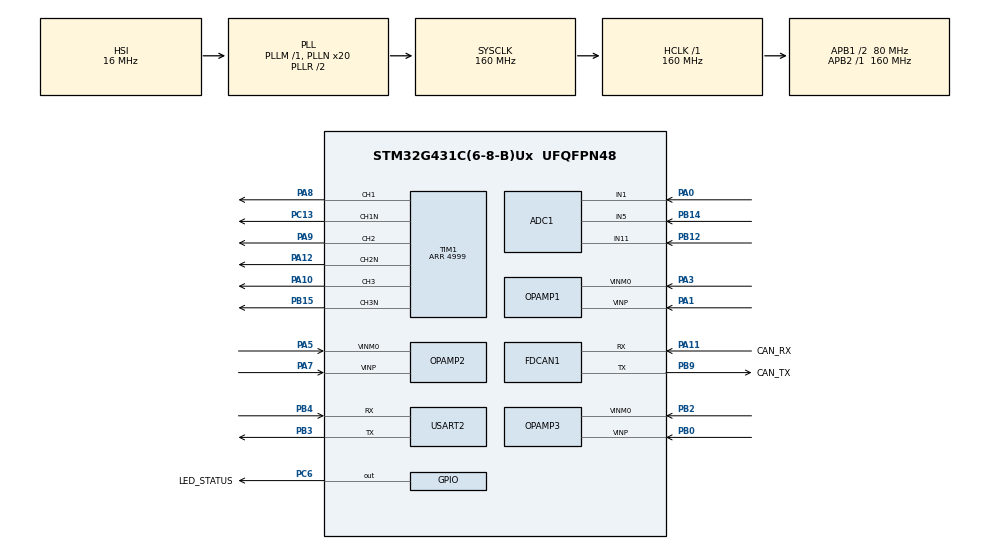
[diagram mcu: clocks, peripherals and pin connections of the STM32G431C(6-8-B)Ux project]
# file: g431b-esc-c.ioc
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ADC1.Channel-0\#ChannelRegularConversion=ADC_CHANNEL_VOPAMP1
ADC1.Channel-1\#ChannelRegularConversion=ADC_CHANNEL_VOPAMP1
ADC1.Channel-2\#ChannelRegularConversion=ADC_CHANNEL_11
ADC1.Channel-3\#ChannelRegularConversion=ADC_CHANNEL_1
ADC1.Channel-4\#ChannelRegularConversion=ADC_CHANNEL_5
ADC1.EOCSelection=ADC_EOC_SEQ_CONV
ADC1.ExternalTrigConv=ADC_EXTERNALTRIG_T1_TRGO
ADC1.NbrOfConversion=5
ADC1.NbrOfConversionFlag=1
ADC1.OffsetNumber-0\#ChannelRegularConversion=ADC_OFFSET_NONE
ADC1.OffsetNumber-1\#ChannelRegularConversion=ADC_OFFSET_NONE
ADC1.OffsetNumber-2\#ChannelRegularConversion=ADC_OFFSET_NONE
ADC1.OffsetNumber-3\#ChannelRegularConversion=ADC_OFFSET_NONE
ADC1.OffsetNumber-4\#ChannelRegularConversion=ADC_OFFSET_NONE
ADC1.Overrun=ADC_OVR_DATA_OVERWRITTEN
ADC1.Rank-0\#ChannelRegularConversion=1
ADC1.Rank-1\#ChannelRegularConversion=2
ADC1.Rank-2\#ChannelRegularConversion=3
ADC1.Rank-3\#ChannelRegularConversion=4
ADC1.Rank-4\#ChannelRegularConversion=5
ADC1.SamplingTime-0\#ChannelRegularConversion=ADC_SAMPLETIME_2CYCLES_5
ADC1.SamplingTime-1\#ChannelRegularConversion=ADC_SAMPLETIME_2CYCLES_5
ADC1.SamplingTime-2\#ChannelRegularConversion=ADC_SAMPLETIME_2CYCLES_5
ADC1.SamplingTime-3\#ChannelRegularConversion=ADC_SAMPLETIME_2CYCLES_5
ADC1.SamplingTime-4\#ChannelRegularConversion=ADC_SAMPLETIME_2CYCLES_5
ADC1.master=1
ADC2.Channel-0\#ChannelRegularConversion=ADC_CHANNEL_VOPAMP2
ADC2.Channel-1\#ChannelRegularConversion=ADC_CHANNEL_VOPAMP2
ADC2.Channel-2\#ChannelRegularConversion=ADC_CHANNEL_VOPAMP3_ADC2
ADC2.EOCSelection=ADC_EOC_SEQ_CONV
ADC2.ExternalTrigConv=ADC_EXTERNALTRIG_T1_TRGO
ADC2.NbrOfConversion=3
ADC2.NbrOfConversionFlag=1
ADC2.OffsetNumber-0\#ChannelRegularConversion=ADC_OFFSET_NONE
ADC2.OffsetNumber-1\#ChannelRegularConversion=ADC_OFFSET_NONE
ADC2.OffsetNumber-2\#ChannelRegularConversion=ADC_OFFSET_NONE
ADC2.Overrun=ADC_OVR_DATA_OVERWRITTEN
ADC2.Rank-0\#ChannelRegularConversion=1
ADC2.Rank-1\#ChannelRegularConversion=2
ADC2.Rank-2\#ChannelRegularConversion=3
ADC2.SamplingTime-0\#ChannelRegularConversion=ADC_SAMPLETIME_2CYCLES_5
ADC2.SamplingTime-1\#ChannelRegularConversion=ADC_SAMPLETIME_2CYCLES_5
ADC2.SamplingTime-2\#ChannelRegularConversion=ADC_SAMPLETIME_2CYCLES_5
Dma.ADC1.2.Direction=DMA_PERIPH_TO_MEMORY
Dma.ADC1.2.EventEnable=DISABLE
Dma.ADC1.2.Instance=DMA1_Channel3
Dma.ADC1.2.MemDataAlignment=DMA_MDATAALIGN_HALFWORD
Dma.ADC1.2.MemInc=DMA_MINC_ENABLE
Dma.ADC1.2.Mode=DMA_CIRCULAR
Dma.ADC1.2.PeriphDataAlignment=DMA_PDATAALIGN_HALFWORD
Dma.ADC1.2.PeriphInc=DMA_PINC_DISABLE
Dma.ADC1.2.Polarity=HAL_DMAMUX_REQ_GEN_RISING
Dma.ADC1.2.Priority=DMA_PRIORITY_LOW
Dma.ADC1.2.RequestNumber=1
Dma.ADC1.2.SignalID=NONE
Dma.ADC1.2.SyncEnable=DISABLE
Dma.ADC1.2.SyncPolarity=HAL_DMAMUX_SYNC_NO_EVENT
Dma.ADC1.2.SyncRequestNumber=1
Dma.ADC1.2.SyncSignalID=NONE
Dma.ADC2.3.Direction=DMA_PERIPH_TO_MEMORY
Dma.ADC2.3.EventEnable=DISABLE
Dma.ADC2.3.Instance=DMA1_Channel4
Dma.ADC2.3.MemDataAlignment=DMA_MDATAALIGN_HALFWORD
Dma.ADC2.3.MemInc=DMA_MINC_ENABLE
Dma.ADC2.3.Mode=DMA_CIRCULAR
Dma.ADC2.3.PeriphDataAlignment=DMA_PDATAALIGN_HALFWORD
Dma.ADC2.3.PeriphInc=DMA_PINC_DISABLE
Dma.ADC2.3.Polarity=HAL_DMAMUX_REQ_GEN_RISING
Dma.ADC2.3.Priority=DMA_PRIORITY_LOW
Dma.ADC2.3.RequestNumber=1
Dma.ADC2.3.SignalID=NONE
Dma.ADC2.3.SyncEnable=DISABLE
Dma.ADC2.3.SyncPolarity=HAL_DMAMUX_SYNC_NO_EVENT
Dma.ADC2.3.SyncRequestNumber=1
Dma.ADC2.3.SyncSignalID=NONE
Dma.Request0=USART2_RX
Dma.Request1=USART2_TX
Dma.Request2=ADC1
Dma.Request3=ADC2
Dma.USART2_RX.0.Direction=DMA_PERIPH_TO_MEMORY
Dma.USART2_RX.0.EventEnable=DISABLE
Dma.USART2_RX.0.Instance=DMA1_Channel1
Dma.USART2_RX.0.MemDataAlignment=DMA_MDATAALIGN_BYTE
Dma.USART2_RX.0.MemInc=DMA_MINC_ENABLE
Dma.USART2_RX.0.Mode=DMA_CIRCULAR
Dma.USART2_RX.0.PeriphDataAlignment=DMA_PDATAALIGN_BYTE
Dma.USART2_RX.0.PeriphInc=DMA_PINC_DISABLE
Dma.USART2_RX.0.Polarity=HAL_DMAMUX_REQ_GEN_RISING
Dma.USART2_RX.0.Priority=DMA_PRIORITY_LOW
Dma.USART2_RX.0.RequestNumber=1
Dma.USART2_RX.0.SignalID=NONE
Dma.USART2_RX.0.SyncEnable=DISABLE
Dma.USART2_RX.0.SyncPolarity=HAL_DMAMUX_SYNC_NO_EVENT
Dma.USART2_RX.0.SyncRequestNumber=1
Dma.USART2_RX.0.SyncSignalID=NONE
Dma.USART2_TX.1.Direction=DMA_MEMORY_TO_PERIPH
Dma.USART2_TX.1.EventEnable=DISABLE
Dma.USART2_TX.1.Instance=DMA1_Channel2
Dma.USART2_TX.1.MemDataAlignment=DMA_MDATAALIGN_BYTE
Dma.USART2_TX.1.MemInc=DMA_MINC_ENABLE
Dma.USART2_TX.1.Mode=DMA_NORMAL
Dma.USART2_TX.1.PeriphDataAlignment=DMA_PDATAALIGN_BYTE
Dma.USART2_TX.1.PeriphInc=DMA_PINC_DISABLE
Dma.USART2_TX.1.Polarity=HAL_DMAMUX_REQ_GEN_RISING
Dma.USART2_TX.1.Priority=DMA_PRIORITY_LOW
Dma.USART2_TX.1.RequestNumber=1
Dma.USART2_TX.1.SignalID=NONE
Dma.USART2_TX.1.SyncEnable=DISABLE
Dma.USART2_TX.1.SyncPolarity=HAL_DMAMUX_SYNC_NO_EVENT
Dma.USART2_TX.1.SyncRequestNumber=1
Dma.USART2_TX.1.SyncSignalID=NONE
FDCAN1.AutoRetransmission=ENABLE
FDCAN1.CalculateBaudRateNominal=1000000
FDCAN1.CalculateTimeBitNominal=1000
FDCAN1.CalculateTimeQuantumNominal=12.5
FDCAN1.DataSyncJumpWidth=7
FDCAN1.DataTimeSeg1=32
FDCAN1.DataTimeSeg2=7
FDCAN1.FrameFormat=FDCAN_FRAME_FD_BRS
FDCAN1.NominalPrescaler=1
FDCAN1.NominalSyncJumpWidth=12
FDCAN1.NominalTimeSeg1=67
FDCAN1.NominalTimeSeg2=12
Mcu.Family=STM32G4
Mcu.Name=STM32G431C(6-8-B)Ux
Mcu.Package=UFQFPN48
NVIC.ADC1_2_IRQn=true\:0\:0\:false\:false\:true\:true\:true\:true
NVIC.DMA1_Channel1_IRQn=true\:0\:0\:false\:false\:true\:false\:true\:true
NVIC.DMA1_Channel2_IRQn=true\:0\:0\:false\:false\:true\:false\:true\:true
NVIC.DMA1_Channel3_IRQn=true\:0\:0\:false\:false\:true\:false\:true\:true
NVIC.DMA1_Channel4_IRQn=true\:0\:0\:false\:false\:true\:false\:true\:true
NVIC.FDCAN1_IT0_IRQn=true\:0\:0\:false\:false\:true\:true\:true\:true
NVIC.PriorityGroup=NVIC_PRIORITYGROUP_4
NVIC.TIM3_IRQn=true\:0\:0\:false\:false\:true\:true\:true\:true
NVIC.USART2_IRQn=true\:0\:0\:false\:false\:true\:true\:true\:true
OPAMP1.PgaGain=OPAMP_PGA_GAIN_16_OR_MINUS_15
OPAMP2.PgaGain=OPAMP_PGA_GAIN_16_OR_MINUS_15
OPAMP3.PgaGain=OPAMP_PGA_GAIN_16_OR_MINUS_15
PA0.Mode=IN1-Single-Ended
PA0.Signal=ADC1_IN1
PA1.Mode=PGA Internally connected_IO0_BIAS
PA1.Signal=OPAMP1_VINP
PA10.Signal=S_TIM1_CH3
PA11.GPIO_Label=CAN_RX
PA11.Mode=FDCAN_Activate
PA11.Signal=FDCAN1_RX
PA12.Mode=PWM Generation2 CH2 CH2N
PA12.Signal=TIM1_CH2N
PA13.GPIO_Label=SWDIO
PA13.Mode=Serial_Wire
PA13.Signal=SYS_JTMS-SWDIO
PA14.GPIO_Label=SWCLK
PA14.Mode=Serial_Wire
PA14.Signal=SYS_JTCK-SWCLK
PA3.Mode=PGA Internally connected_IO0_BIAS
PA3.Signal=OPAMP1_VINM0
PA5.Mode=PGA Internally connected_IO0_BIAS
PA5.Signal=OPAMP2_VINM0
PA7.Mode=PGA Internally connected_IO0_BIAS
PA7.Signal=OPAMP2_VINP
PA8.Signal=S_TIM1_CH1
PA9.Signal=S_TIM1_CH2
PB0.Mode=PGA Internally connected_IO0_BIAS
PB0.Signal=OPAMP3_VINP
PB12.Mode=IN11-Single-Ended
PB12.Signal=ADC1_IN11
PB14.Mode=IN5-Single-Ended
PB14.Signal=ADC1_IN5
PB15.Mode=PWM Generation3 CH3 CH3N
PB15.Signal=TIM1_CH3N
PB2.Mode=PGA Internally connected_IO0_BIAS
PB2.Signal=OPAMP3_VINM0
PB3.Mode=Asynchronous
PB3.Signal=USART2_TX
PB4.Mode=Asynchronous
PB4.Signal=USART2_RX
PB9.GPIO_Label=CAN_TX
PB9.Mode=FDCAN_Activate
PB9.Signal=FDCAN1_TX
PC13.Mode=PWM Generation1 CH1 CH1N
PC13.Signal=TIM1_CH1N
PC6.GPIO_Label=LED_STATUS
PC6.Signal=GPIO_Output
PF0-OSC_IN.Mode=HSE-External-Oscillator
PF0-OSC_IN.Signal=RCC_OSC_IN
PF1-OSC_OUT.Mode=HSE-External-Oscillator
PF1-OSC_OUT.Signal=RCC_OSC_OUT
ProjectManager.HeapSize=0x200
ProjectManager.StackSize=0x400
ProjectManager.TargetToolchain=STM32CubeIDE
RCC.ADC12Freq_Value=160000000
RCC.AHBFreq_Value=160000000
RCC.APB1CLKDivider=RCC_HCLK_DIV2
RCC.APB1Freq_Value=80000000
RCC.APB1TimFreq_Value=160000000
RCC.APB2Freq_Value=160000000
RCC.APB2TimFreq_Value=160000000
RCC.CortexFreq_Value=160000000
RCC.EXTERNAL_CLOCK_VALUE=12288000
RCC.HCLKFreq_Value=160000000
RCC.HSE_VALUE=8000000
RCC.HSI48_VALUE=48000000
RCC.HSI_VALUE=16000000
RCC.LSE_VALUE=32768
RCC.PLLN=20
RCC.PLLQ=RCC_PLLQ_DIV4
RCC.SYSCLKFreq_VALUE=160000000
RCC.SYSCLKSource=RCC_SYSCLKSOURCE_PLLCLK
RCC.USBFreq_Value=80000000
RCC.VCOOutputFreq_Value=320000000
SH.S_TIM1_CH1.0=TIM1_CH1,PWM Generation1 CH1 CH1N
SH.S_TIM1_CH2.0=TIM1_CH2,PWM Generation2 CH2 CH2N
SH.S_TIM1_CH3.0=TIM1_CH3,PWM Generation3 CH3 CH3N
TIM1.Channel-PWM\ Generation1\ CH1\ CH1N=TIM_CHANNEL_1
TIM1.Channel-PWM\ Generation2\ CH2\ CH2N=TIM_CHANNEL_2
TIM1.Channel-PWM\ Generation3\ CH3\ CH3N=TIM_CHANNEL_3
TIM1.CounterMode=TIM_COUNTERMODE_CENTERALIGNED1
TIM1.DeadTime=128
TIM1.PeriodNoDither=4999
TIM1.TIM_MasterOutputTrigger=TIM_TRGO_UPDATE
TIM2.PeriodNoDither=4294967295
TIM2.Prescaler=159
TIM3.PeriodNoDither=999
TIM3.Prescaler=159
USART2.RXFIFOThreshold=RXFIFO_THRESHOLD_HALFFULL
USART2.TXFIFOThreshold=TXFIFO_THRESHOLD_EMPTY
USART2.VirtualMode-Asynchronous=VM_ASYNC
VP_ADC1_OPAMP_INTERNAL1.Mode=IN-OPAMP1
VP_ADC2_OPAMP_INTERNAL2.Mode=IN-OPAMP2
VP_ADC2_OPAMP_INTERNAL3.Mode=IN-OPAMP3
VP_SYS_VS_DBSignals.Mode=DisableDeadBatterySignals
VP_TIM1_VS_ClockSourceINT.Mode=Internal
VP_TIM2_VS_ClockSourceINT.Mode=Internal
VP_TIM3_VS_ClockSourceINT.Mode=Internal
board=custom

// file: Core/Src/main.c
/* USER CODE BEGIN Header */
/**
  ******************************************************************************
  * @file           : main.c
  * @brief          : Main program body
  ******************************************************************************
  * @attention
  *
  * Copyright (c) 2025 STMicroelectronics.
  * All rights reserved.
  *
  * This software is licensed under terms that can be found in the LICENSE file
  * in the root directory of this software component.
  * If no LICENSE file comes with this software, it is provided AS-IS.
  *
  ******************************************************************************
  */
/* USER CODE END Header */
#include "main.h"

ADC_HandleTypeDef hadc1;
ADC_HandleTypeDef hadc2;
DMA_HandleTypeDef hdma_adc1;
DMA_HandleTypeDef hdma_adc2;

FDCAN_HandleTypeDef hfdcan1;

OPAMP_HandleTypeDef hopamp1;
OPAMP_HandleTypeDef hopamp2;
OPAMP_HandleTypeDef hopamp3;

TIM_HandleTypeDef htim1;
TIM_HandleTypeDef htim2;
TIM_HandleTypeDef htim3;

UART_HandleTypeDef huart2;
DMA_HandleTypeDef hdma_usart2_rx;
DMA_HandleTypeDef hdma_usart2_tx;

void SystemClock_Config(void);
static void MX_GPIO_Init(void);
static void MX_DMA_Init(void);
static void MX_FDCAN1_Init(void);
static void MX_USART2_UART_Init(void);
static void MX_TIM2_Init(void);
static void MX_TIM1_Init(void);
static void MX_ADC1_Init(void);
static void MX_OPAMP1_Init(void);
static void MX_OPAMP2_Init(void);
static void MX_OPAMP3_Init(void);
static void MX_ADC2_Init(void);
static void MX_TIM3_Init(void);

int main(void)
{

  /* MCU Configuration--------------------------------------------------------*/

  /* Reset of all peripherals, Initializes the Flash interface and the Systick. */
  HAL_Init();

  /* Configure the system clock */
  SystemClock_Config();

  /* Initialize all configured peripherals */
  MX_GPIO_Init();
  MX_DMA_Init();
  MX_FDCAN1_Init();
  MX_USART2_UART_Init();
  MX_TIM2_Init();
  MX_TIM1_Init();
  MX_ADC1_Init();
  MX_OPAMP1_Init();
  MX_OPAMP2_Init();
  MX_OPAMP3_Init();
  MX_ADC2_Init();
  MX_TIM3_Init();
  /* USER CODE BEGIN 2 */

  HAL_TIM_Base_Start(&htim2);
  __HAL_TIM_SET_COUNTER(&htim2, 0U);
  __HAL_DBGMCU_FREEZE_TIM2();

  extern void QPC_start(void);
  QPC_start();
  /* USER CODE END 2 */

  /* Infinite loop */
  while (1)
  {

  }
}

void SystemClock_Config(void)
{
  RCC_OscInitTypeDef RCC_OscInitStruct = {0};
  RCC_ClkInitTypeDef RCC_ClkInitStruct = {0};

  /** Configure the main internal regulator output voltage
  */
  HAL_PWREx_ControlVoltageScaling(PWR_REGULATOR_VOLTAGE_SCALE1_BOOST);

  /** Initializes the RCC Oscillators according to the specified parameters
  * in the RCC_OscInitTypeDef structure.
  */
  RCC_OscInitStruct.OscillatorType = RCC_OSCILLATORTYPE_HSI;
  RCC_OscInitStruct.HSIState = RCC_HSI_ON;
  RCC_OscInitStruct.HSICalibrationValue = RCC_HSICALIBRATION_DEFAULT;
  RCC_OscInitStruct.PLL.PLLState = RCC_PLL_ON;
  RCC_OscInitStruct.PLL.PLLSource = RCC_PLLSOURCE_HSI;
  RCC_OscInitStruct.PLL.PLLM = RCC_PLLM_DIV1;
  RCC_OscInitStruct.PLL.PLLN = 20;
  RCC_OscInitStruct.PLL.PLLP = RCC_PLLP_DIV2;
  RCC_OscInitStruct.PLL.PLLQ = RCC_PLLQ_DIV4;
  RCC_OscInitStruct.PLL.PLLR = RCC_PLLR_DIV2;
  if (HAL_RCC_OscConfig(&RCC_OscInitStruct) != HAL_OK)
  {
    Error_Handler();
  }

  /** Initializes the CPU, AHB and APB buses clocks
  */
  RCC_ClkInitStruct.ClockType = RCC_CLOCKTYPE_HCLK|RCC_CLOCKTYPE_SYSCLK
                              |RCC_CLOCKTYPE_PCLK1|RCC_CLOCKTYPE_PCLK2;
  RCC_ClkInitStruct.SYSCLKSource = RCC_SYSCLKSOURCE_PLLCLK;
  RCC_ClkInitStruct.AHBCLKDivider = RCC_SYSCLK_DIV1;
  RCC_ClkInitStruct.APB1CLKDivider = RCC_HCLK_DIV2;
  RCC_ClkInitStruct.APB2CLKDivider = RCC_HCLK_DIV1;

  if (HAL_RCC_ClockConfig(&RCC_ClkInitStruct, FLASH_LATENCY_4) != HAL_OK)
  {
    Error_Handler();
  }
}

static void MX_ADC1_Init(void)
{

  ADC_MultiModeTypeDef multimode = {0};
  ADC_ChannelConfTypeDef sConfig = {0};

  /** Common config
  */
  hadc1.Instance = ADC1;
  hadc1.Init.ClockPrescaler = ADC_CLOCK_SYNC_PCLK_DIV4;
  hadc1.Init.Resolution = ADC_RESOLUTION_12B;
  hadc1.Init.DataAlign = ADC_DATAALIGN_RIGHT;
  hadc1.Init.GainCompensation = 0;
  hadc1.Init.ScanConvMode = ADC_SCAN_ENABLE;
  hadc1.Init.EOCSelection = ADC_EOC_SEQ_CONV;
  hadc1.Init.LowPowerAutoWait = DISABLE;
  hadc1.Init.ContinuousConvMode = DISABLE;
  hadc1.Init.NbrOfConversion = 5;
  hadc1.Init.DiscontinuousConvMode = DISABLE;
  hadc1.Init.ExternalTrigConv = ADC_EXTERNALTRIG_T1_TRGO;
  hadc1.Init.ExternalTrigConvEdge = ADC_EXTERNALTRIGCONVEDGE_RISING;
  hadc1.Init.DMAContinuousRequests = DISABLE;
  hadc1.Init.Overrun = ADC_OVR_DATA_OVERWRITTEN;
  hadc1.Init.OversamplingMode = DISABLE;
  if (HAL_ADC_Init(&hadc1) != HAL_OK)
  {
    Error_Handler();
  }

  /** Configure the ADC multi-mode
  */
  multimode.Mode = ADC_MODE_INDEPENDENT;
  if (HAL_ADCEx_MultiModeConfigChannel(&hadc1, &multimode) != HAL_OK)
  {
    Error_Handler();
  }

  /** Configure Regular Channel
  */
  sConfig.Channel = ADC_CHANNEL_VOPAMP1;
  sConfig.Rank = ADC_REGULAR_RANK_1;
  sConfig.SamplingTime = ADC_SAMPLETIME_2CYCLES_5;
  sConfig.SingleDiff = ADC_SINGLE_ENDED;
  sConfig.OffsetNumber = ADC_OFFSET_NONE;
  sConfig.Offset = 0;
  if (HAL_ADC_ConfigChannel(&hadc1, &sConfig) != HAL_OK)
  {
    Error_Handler();
  }

  /** Configure Regular Channel
  */
  sConfig.Rank = ADC_REGULAR_RANK_2;
  if (HAL_ADC_ConfigChannel(&hadc1, &sConfig) != HAL_OK)
  {
    Error_Handler();
  }

  /** Configure Regular Channel
  */
  sConfig.Channel = ADC_CHANNEL_11;
  sConfig.Rank = ADC_REGULAR_RANK_3;
  if (HAL_ADC_ConfigChannel(&hadc1, &sConfig) != HAL_OK)
  {
    Error_Handler();
  }

  /** Configure Regular Channel
  */
  sConfig.Channel = ADC_CHANNEL_1;
  sConfig.Rank = ADC_REGULAR_RANK_4;
  if (HAL_ADC_ConfigChannel(&hadc1, &sConfig) != HAL_OK)
  {
    Error_Handler();
  }

  /** Configure Regular Channel
  */
  sConfig.Channel = ADC_CHANNEL_5;
  sConfig.Rank = ADC_REGULAR_RANK_5;
  if (HAL_ADC_ConfigChannel(&hadc1, &sConfig) != HAL_OK)
  {
    Error_Handler();
  }

}

static void MX_ADC2_Init(void)
{

  ADC_ChannelConfTypeDef sConfig = {0};

  /** Common config
  */
  hadc2.Instance = ADC2;
  hadc2.Init.ClockPrescaler = ADC_CLOCK_SYNC_PCLK_DIV4;
  hadc2.Init.Resolution = ADC_RESOLUTION_12B;
  hadc2.Init.DataAlign = ADC_DATAALIGN_RIGHT;
  hadc2.Init.GainCompensation = 0;
  hadc2.Init.ScanConvMode = ADC_SCAN_ENABLE;
  hadc2.Init.EOCSelection = ADC_EOC_SEQ_CONV;
  hadc2.Init.LowPowerAutoWait = DISABLE;
  hadc2.Init.ContinuousConvMode = DISABLE;
  hadc2.Init.NbrOfConversion = 3;
  hadc2.Init.DiscontinuousConvMode = DISABLE;
  hadc2.Init.ExternalTrigConv = ADC_EXTERNALTRIG_T1_TRGO;
  hadc2.Init.ExternalTrigConvEdge = ADC_EXTERNALTRIGCONVEDGE_RISING;
  hadc2.Init.DMAContinuousRequests = DISABLE;
  hadc2.Init.Overrun = ADC_OVR_DATA_OVERWRITTEN;
  hadc2.Init.OversamplingMode = DISABLE;
  if (HAL_ADC_Init(&hadc2) != HAL_OK)
  {
    Error_Handler();
  }

  /** Configure Regular Channel
  */
  sConfig.Channel = ADC_CHANNEL_VOPAMP2;
  sConfig.Rank = ADC_REGULAR_RANK_1;
  sConfig.SamplingTime = ADC_SAMPLETIME_2CYCLES_5;
  sConfig.SingleDiff = ADC_SINGLE_ENDED;
  sConfig.OffsetNumber = ADC_OFFSET_NONE;
  sConfig.Offset = 0;
  if (HAL_ADC_ConfigChannel(&hadc2, &sConfig) != HAL_OK)
  {
    Error_Handler();
  }

  /** Configure Regular Channel
  */
  sConfig.Rank = ADC_REGULAR_RANK_2;
  if (HAL_ADC_ConfigChannel(&hadc2, &sConfig) != HAL_OK)
  {
    Error_Handler();
  }

  /** Configure Regular Channel
  */
  sConfig.Channel = ADC_CHANNEL_VOPAMP3_ADC2;
  sConfig.Rank = ADC_REGULAR_RANK_3;
  if (HAL_ADC_ConfigChannel(&hadc2, &sConfig) != HAL_OK)
  {
    Error_Handler();
  }

}

static void MX_FDCAN1_Init(void)
{

  hfdcan1.Instance = FDCAN1;
  hfdcan1.Init.ClockDivider = FDCAN_CLOCK_DIV1;
  hfdcan1.Init.FrameFormat = FDCAN_FRAME_FD_BRS;
  hfdcan1.Init.Mode = FDCAN_MODE_NORMAL;
  hfdcan1.Init.AutoRetransmission = ENABLE;
  hfdcan1.Init.TransmitPause = DISABLE;
  hfdcan1.Init.ProtocolException = DISABLE;
  hfdcan1.Init.NominalPrescaler = 1;
  hfdcan1.Init.NominalSyncJumpWidth = 12;
  hfdcan1.Init.NominalTimeSeg1 = 67;
  hfdcan1.Init.NominalTimeSeg2 = 12;
  hfdcan1.Init.DataPrescaler = 1;
  hfdcan1.Init.DataSyncJumpWidth = 7;
  hfdcan1.Init.DataTimeSeg1 = 32;
  hfdcan1.Init.DataTimeSeg2 = 7;
  hfdcan1.Init.StdFiltersNbr = 0;
  hfdcan1.Init.ExtFiltersNbr = 0;
  hfdcan1.Init.TxFifoQueueMode = FDCAN_TX_FIFO_OPERATION;
  if (HAL_FDCAN_Init(&hfdcan1) != HAL_OK)
  {
    Error_Handler();
  }

}

static void MX_OPAMP1_Init(void)
{

  hopamp1.Instance = OPAMP1;
  hopamp1.Init.PowerMode = OPAMP_POWERMODE_NORMALSPEED;
  hopamp1.Init.Mode = OPAMP_PGA_MODE;
  hopamp1.Init.NonInvertingInput = OPAMP_NONINVERTINGINPUT_IO0;
  hopamp1.Init.InternalOutput = ENABLE;
  hopamp1.Init.TimerControlledMuxmode = OPAMP_TIMERCONTROLLEDMUXMODE_DISABLE;
  hopamp1.Init.PgaConnect = OPAMP_PGA_CONNECT_INVERTINGINPUT_IO0_BIAS;
  hopamp1.Init.PgaGain = OPAMP_PGA_GAIN_16_OR_MINUS_15;
  hopamp1.Init.UserTrimming = OPAMP_TRIMMING_FACTORY;
  if (HAL_OPAMP_Init(&hopamp1) != HAL_OK)
  {
    Error_Handler();
  }

}

static void MX_OPAMP2_Init(void)
{

  hopamp2.Instance = OPAMP2;
  hopamp2.Init.PowerMode = OPAMP_POWERMODE_NORMALSPEED;
  hopamp2.Init.Mode = OPAMP_PGA_MODE;
  hopamp2.Init.NonInvertingInput = OPAMP_NONINVERTINGINPUT_IO0;
  hopamp2.Init.InternalOutput = ENABLE;
  hopamp2.Init.TimerControlledMuxmode = OPAMP_TIMERCONTROLLEDMUXMODE_DISABLE;
  hopamp2.Init.PgaConnect = OPAMP_PGA_CONNECT_INVERTINGINPUT_IO0_BIAS;
  hopamp2.Init.PgaGain = OPAMP_PGA_GAIN_16_OR_MINUS_15;
  hopamp2.Init.UserTrimming = OPAMP_TRIMMING_FACTORY;
  if (HAL_OPAMP_Init(&hopamp2) != HAL_OK)
  {
    Error_Handler();
  }

}

static void MX_OPAMP3_Init(void)
{

  hopamp3.Instance = OPAMP3;
  hopamp3.Init.PowerMode = OPAMP_POWERMODE_NORMALSPEED;
  hopamp3.Init.Mode = OPAMP_PGA_MODE;
  hopamp3.Init.NonInvertingInput = OPAMP_NONINVERTINGINPUT_IO0;
  hopamp3.Init.InternalOutput = ENABLE;
  hopamp3.Init.TimerControlledMuxmode = OPAMP_TIMERCONTROLLEDMUXMODE_DISABLE;
  hopamp3.Init.PgaConnect = OPAMP_PGA_CONNECT_INVERTINGINPUT_IO0_BIAS;
  hopamp3.Init.PgaGain = OPAMP_PGA_GAIN_16_OR_MINUS_15;
  hopamp3.Init.UserTrimming = OPAMP_TRIMMING_FACTORY;
  if (HAL_OPAMP_Init(&hopamp3) != HAL_OK)
  {
    Error_Handler();
  }

}

static void MX_TIM1_Init(void)
{

  TIM_ClockConfigTypeDef sClockSourceConfig = {0};
  TIM_MasterConfigTypeDef sMasterConfig = {0};
  TIM_OC_InitTypeDef sConfigOC = {0};
  TIM_BreakDeadTimeConfigTypeDef sBreakDeadTimeConfig = {0};

  htim1.Instance = TIM1;
  htim1.Init.Prescaler = 0;
  htim1.Init.CounterMode = TIM_COUNTERMODE_CENTERALIGNED1;
  htim1.Init.Period = 4999;
  htim1.Init.ClockDivision = TIM_CLOCKDIVISION_DIV1;
  htim1.Init.RepetitionCounter = 0;
  htim1.Init.AutoReloadPreload = TIM_AUTORELOAD_PRELOAD_DISABLE;
  if (HAL_TIM_Base_Init(&htim1) != HAL_OK)
  {
    Error_Handler();
  }
  sClockSourceConfig.ClockSource = TIM_CLOCKSOURCE_INTERNAL;
  if (HAL_TIM_ConfigClockSource(&htim1, &sClockSourceConfig) != HAL_OK)
  {
    Error_Handler();
  }
  if (HAL_TIM_PWM_Init(&htim1) != HAL_OK)
  {
    Error_Handler();
  }
  sMasterConfig.MasterOutputTrigger = TIM_TRGO_UPDATE;
  sMasterConfig.MasterOutputTrigger2 = TIM_TRGO2_RESET;
  sMasterConfig.MasterSlaveMode = TIM_MASTERSLAVEMODE_DISABLE;
  if (HAL_TIMEx_MasterConfigSynchronization(&htim1, &sMasterConfig) != HAL_OK)
  {
    Error_Handler();
  }
  sConfigOC.OCMode = TIM_OCMODE_PWM1;
  sConfigOC.Pulse = 0;
  sConfigOC.OCPolarity = TIM_OCPOLARITY_HIGH;
  sConfigOC.OCNPolarity = TIM_OCNPOLARITY_HIGH;
  sConfigOC.OCFastMode = TIM_OCFAST_DISABLE;
  sConfigOC.OCIdleState = TIM_OCIDLESTATE_RESET;
  sConfigOC.OCNIdleState = TIM_OCNIDLESTATE_RESET;
  if (HAL_TIM_PWM_ConfigChannel(&htim1, &sConfigOC, TIM_CHANNEL_1) != HAL_OK)
  {
    Error_Handler();
  }
  if (HAL_TIM_PWM_ConfigChannel(&htim1, &sConfigOC, TIM_CHANNEL_2) != HAL_OK)
  {
    Error_Handler();
  }
  if (HAL_TIM_PWM_ConfigChannel(&htim1, &sConfigOC, TIM_CHANNEL_3) != HAL_OK)
  {
    Error_Handler();
  }
  sBreakDeadTimeConfig.OffStateRunMode = TIM_OSSR_DISABLE;
  sBreakDeadTimeConfig.OffStateIDLEMode = TIM_OSSI_DISABLE;
  sBreakDeadTimeConfig.LockLevel = TIM_LOCKLEVEL_OFF;
  sBreakDeadTimeConfig.DeadTime = 128;
  sBreakDeadTimeConfig.BreakState = TIM_BREAK_DISABLE;
  sBreakDeadTimeConfig.BreakPolarity = TIM_BREAKPOLARITY_HIGH;
  sBreakDeadTimeConfig.BreakFilter = 0;
  sBreakDeadTimeConfig.BreakAFMode = TIM_BREAK_AFMODE_INPUT;
  sBreakDeadTimeConfig.Break2State = TIM_BREAK2_DISABLE;
  sBreakDeadTimeConfig.Break2Polarity = TIM_BREAK2POLARITY_HIGH;
  sBreakDeadTimeConfig.Break2Filter = 0;
  sBreakDeadTimeConfig.Break2AFMode = TIM_BREAK_AFMODE_INPUT;
  sBreakDeadTimeConfig.AutomaticOutput = TIM_AUTOMATICOUTPUT_DISABLE;
  if (HAL_TIMEx_ConfigBreakDeadTime(&htim1, &sBreakDeadTimeConfig) != HAL_OK)
  {
    Error_Handler();
  }
  HAL_TIM_MspPostInit(&htim1);

}

static void MX_TIM2_Init(void)
{

  TIM_ClockConfigTypeDef sClockSourceConfig = {0};
  TIM_MasterConfigTypeDef sMasterConfig = {0};

  htim2.Instance = TIM2;
  htim2.Init.Prescaler = 159;
  htim2.Init.CounterMode = TIM_COUNTERMODE_UP;
  htim2.Init.Period = 4294967295;
  htim2.Init.ClockDivision = TIM_CLOCKDIVISION_DIV1;
  htim2.Init.AutoReloadPreload = TIM_AUTORELOAD_PRELOAD_DISABLE;
  if (HAL_TIM_Base_Init(&htim2) != HAL_OK)
  {
    Error_Handler();
  }
  sClockSourceConfig.ClockSource = TIM_CLOCKSOURCE_INTERNAL;
  if (HAL_TIM_ConfigClockSource(&htim2, &sClockSourceConfig) != HAL_OK)
  {
    Error_Handler();
  }
  sMasterConfig.MasterOutputTrigger = TIM_TRGO_RESET;
  sMasterConfig.MasterSlaveMode = TIM_MASTERSLAVEMODE_DISABLE;
  if (HAL_TIMEx_MasterConfigSynchronization(&htim2, &sMasterConfig) != HAL_OK)
  {
    Error_Handler();
  }

}

static void MX_TIM3_Init(void)
{

  TIM_ClockConfigTypeDef sClockSourceConfig = {0};
  TIM_MasterConfigTypeDef sMasterConfig = {0};

  htim3.Instance = TIM3;
  htim3.Init.Prescaler = 159;
  htim3.Init.CounterMode = TIM_COUNTERMODE_UP;
  htim3.Init.Period = 999;
  htim3.Init.ClockDivision = TIM_CLOCKDIVISION_DIV1;
  htim3.Init.AutoReloadPreload = TIM_AUTORELOAD_PRELOAD_DISABLE;
  if (HAL_TIM_Base_Init(&htim3) != HAL_OK)
  {
    Error_Handler();
  }
  sClockSourceConfig.ClockSource = TIM_CLOCKSOURCE_INTERNAL;
  if (HAL_TIM_ConfigClockSource(&htim3, &sClockSourceConfig) != HAL_OK)
  {
    Error_Handler();
  }
  sMasterConfig.MasterOutputTrigger = TIM_TRGO_RESET;
  sMasterConfig.MasterSlaveMode = TIM_MASTERSLAVEMODE_DISABLE;
  if (HAL_TIMEx_MasterConfigSynchronization(&htim3, &sMasterConfig) != HAL_OK)
  {
    Error_Handler();
  }

}

static void MX_USART2_UART_Init(void)
{

  huart2.Instance = USART2;
  huart2.Init.BaudRate = 115200;
  huart2.Init.WordLength = UART_WORDLENGTH_8B;
  huart2.Init.StopBits = UART_STOPBITS_1;
  huart2.Init.Parity = UART_PARITY_NONE;
  huart2.Init.Mode = UART_MODE_TX_RX;
  huart2.Init.HwFlowCtl = UART_HWCONTROL_NONE;
  huart2.Init.OverSampling = UART_OVERSAMPLING_16;
  huart2.Init.OneBitSampling = UART_ONE_BIT_SAMPLE_DISABLE;
  huart2.Init.ClockPrescaler = UART_PRESCALER_DIV1;
  huart2.AdvancedInit.AdvFeatureInit = UART_ADVFEATURE_NO_INIT;
  if (HAL_UART_Init(&huart2) != HAL_OK)
  {
    Error_Handler();
  }
  if (HAL_UARTEx_SetTxFifoThreshold(&huart2, UART_TXFIFO_THRESHOLD_8_8) != HAL_OK)
  {
    Error_Handler();
  }
  if (HAL_UARTEx_SetRxFifoThreshold(&huart2, UART_RXFIFO_THRESHOLD_1_2) != HAL_OK)
  {
    Error_Handler();
  }
  if (HAL_UARTEx_DisableFifoMode(&huart2) != HAL_OK)
  {
    Error_Handler();
  }

}

static void MX_DMA_Init(void)
{

  /* DMA controller clock enable */
  __HAL_RCC_DMAMUX1_CLK_ENABLE();
  __HAL_RCC_DMA1_CLK_ENABLE();

  /* DMA interrupt init */
  /* DMA1_Channel1_IRQn interrupt configuration */
  HAL_NVIC_SetPriority(DMA1_Channel1_IRQn, 0, 0);
  HAL_NVIC_EnableIRQ(DMA1_Channel1_IRQn);
  /* DMA1_Channel2_IRQn interrupt configuration */
  HAL_NVIC_SetPriority(DMA1_Channel2_IRQn, 0, 0);
  HAL_NVIC_EnableIRQ(DMA1_Channel2_IRQn);
  /* DMA1_Channel3_IRQn interrupt configuration */
  HAL_NVIC_SetPriority(DMA1_Channel3_IRQn, 0, 0);
  HAL_NVIC_EnableIRQ(DMA1_Channel3_IRQn);
  /* DMA1_Channel4_IRQn interrupt configuration */
  HAL_NVIC_SetPriority(DMA1_Channel4_IRQn, 0, 0);
  HAL_NVIC_EnableIRQ(DMA1_Channel4_IRQn);

}

static void MX_GPIO_Init(void)
{
  GPIO_InitTypeDef GPIO_InitStruct = {0};

  /* GPIO Ports Clock Enable */
  __HAL_RCC_GPIOC_CLK_ENABLE();
  __HAL_RCC_GPIOF_CLK_ENABLE();
  __HAL_RCC_GPIOA_CLK_ENABLE();
  __HAL_RCC_GPIOB_CLK_ENABLE();

  /*Configure GPIO pin Output Level */
  HAL_GPIO_WritePin(LED_STATUS_GPIO_Port, LED_STATUS_Pin, GPIO_PIN_RESET);

  /*Configure GPIO pin : LED_STATUS_Pin */
  GPIO_InitStruct.Pin = LED_STATUS_Pin;
  GPIO_InitStruct.Mode = GPIO_MODE_OUTPUT_PP;
  GPIO_InitStruct.Pull = GPIO_NOPULL;
  GPIO_InitStruct.Speed = GPIO_SPEED_FREQ_LOW;
  HAL_GPIO_Init(LED_STATUS_GPIO_Port, &GPIO_InitStruct);

}

/* USER CODE BEGIN 4 */
uint32_t TIMER_1us_count(void)
{
    return __HAL_TIM_GET_COUNTER(&htim2);
}

/* USER CODE END 4 */

void Error_Handler(void)
{
  __disable_irq();
  while (1)
  {
  }
}
